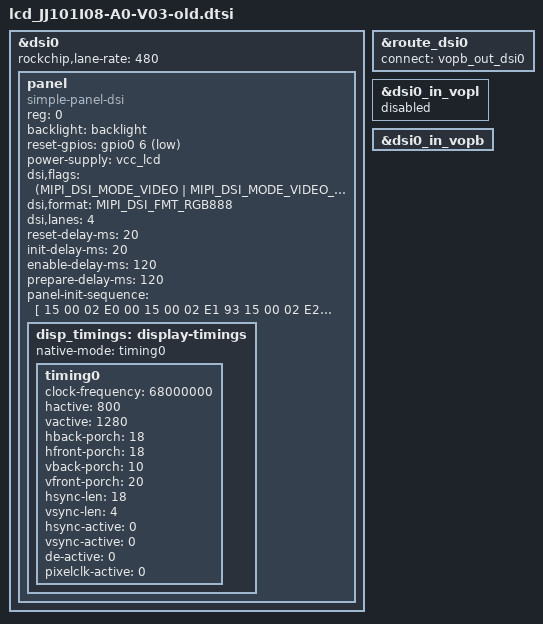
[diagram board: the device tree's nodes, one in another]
/*
***lcd_JJ101I08-A0-V03 20201125 by lxr***
*/
&dsi0 {
	status = "okay";
	rockchip,lane-rate = <480>;

	panel: panel {
		compatible = "simple-panel-dsi";
		reg = <0>;
		backlight = <&backlight>;
		//enable-gpios = <&gpio7 3 GPIO_ACTIVE_HIGH>;
		//reset-gpios = <0>;
		reset-gpios = <&gpio0 6 GPIO_ACTIVE_LOW>;// V2.2A
		power-supply = <&vcc_lcd>;
		dsi,flags = <(MIPI_DSI_MODE_VIDEO | MIPI_DSI_MODE_VIDEO_BURST | MIPI_DSI_MODE_EOT_PACKET | MIPI_DSI_MODE_LPM)>;
		dsi,format = <MIPI_DSI_FMT_RGB888>;
		dsi,lanes = <4>;
		reset-delay-ms = <20>;
		init-delay-ms = <20>;
		enable-delay-ms = <120>;
		prepare-delay-ms = <120>;
		status = "okay";
		
		panel-init-sequence = [
                15 00 02 E0 00 
		15 00 02 E1 93 
		15 00 02 E2 65 
		15 00 02 E3 F8 
		15 00 02 80 03 
		15 00 02 E0 01 
		//15 00 02 00 00 
		15 00 02 01 67 
		//15 00 02 03 00 
		//15 00 02 04 6C 
		15 00 02 17 00 
		15 00 02 18 BF 
		15 00 02 19 01 
		15 00 02 1A 00 
		15 00 02 1B BF 
		15 00 02 1C 01 
		15 00 02 1F 70 
		15 00 02 20 2D 
		15 00 02 21 2D 
		15 00 02 22 7E 
		15 00 02 35 28 
		15 00 02 37 19 
		15 00 02 38 05 
		15 00 02 39 00 
		15 00 02 3A 01 
		15 00 02 3C 7C 
		15 00 02 3D FF 
		15 00 02 3E FF 
		15 00 02 3F 7F 
		15 00 02 40 06 
		15 00 02 41 A0 
		15 00 02 43 1E 
		15 00 02 44 0B 
		15 00 02 45 28 
		15 00 02 55 0F 
		15 00 02 57 A8 
		15 00 02 59 0A 
		15 00 02 5A 2E 
		15 00 02 5B 1A 
		15 00 02 5C 15 
		15 00 02 5D 7F 
		15 00 02 5E 64 
		15 00 02 5F 53 
		15 00 02 60 47 
		15 00 02 61 43 
		15 00 02 62 33 
		15 00 02 63 37 
		15 00 02 64 21 
		15 00 02 65 39 
		15 00 02 66 37 
		15 00 02 67 34 
		15 00 02 68 50 
		15 00 02 69 3D 
		15 00 02 6A 44 
		15 00 02 6B 36 
		15 00 02 6C 34 
		15 00 02 6D 25 
		15 00 02 6E 15 
		15 00 02 6F 02 
		15 00 02 70 7F 
		15 00 02 71 64 
		15 00 02 72 53 
		15 00 02 73 47
		15 00 02 74 43 
		15 00 02 75 33 
		15 00 02 76 37 
		15 00 02 77 21 
		15 00 02 78 39 
		15 00 02 79 37 
		15 00 02 7A 34 
		15 00 02 7B 50 
		15 00 02 7C 3D 
		15 00 02 7D 44 
		15 00 02 7E 36 
		15 00 02 7F 34 
		15 00 02 80 25 
		15 00 02 81 15 
		15 00 02 82 02 
		15 00 02 E0 02 
		15 00 02 00 52 
		15 00 02 01 55 
		15 00 02 02 55 
		15 00 02 03 50 
		15 00 02 04 77 
		15 00 02 05 57 
		15 00 02 06 55 
		15 00 02 07 4E 
		15 00 02 08 4C 
		15 00 02 09 5F 
		15 00 02 0A 4A 
		15 00 02 0B 48 
		15 00 02 0C 55 
		15 00 02 0D 46 
		15 00 02 0E 44 
		15 00 02 0F 40 
		15 00 02 10 55 
		15 00 02 11 55 
		15 00 02 12 55 
		15 00 02 13 55 
		15 00 02 14 55 
		15 00 02 15 55 
		15 00 02 16 53 
		15 00 02 17 55 
		15 00 02 18 55 
		15 00 02 19 51 
		15 00 02 1A 77 
		15 00 02 1B 57 
		15 00 02 1C 55 
		15 00 02 1D 4F 
		15 00 02 1E 4D 
		15 00 02 1F 5F 
		15 00 02 20 4B 
		15 00 02 21 49 
		15 00 02 22 55 
		15 00 02 23 47 
		15 00 02 24 45 
		15 00 02 25 41 
		15 00 02 26 55 
		15 00 02 27 55 
		15 00 02 28 55 
		15 00 02 29 55 
		15 00 02 2A 55 
		15 00 02 2B 55 
		15 00 02 2C 13 
		15 00 02 2D 15 
		15 00 02 2E 15 
		15 00 02 2F 01 
		15 00 02 30 37 
		15 00 02 31 17 
		15 00 02 32 15 
		15 00 02 33 0D 
		15 00 02 34 0F 
		15 00 02 35 15 
		15 00 02 36 05 
		15 00 02 37 07 
		15 00 02 38 15 
		15 00 02 39 09 
		15 00 02 3A 0B 
		15 00 02 3B 11 
		15 00 02 3C 15 
		15 00 02 3D 15 
		15 00 02 3E 15 
		15 00 02 3F 15 
		15 00 02 40 15 
		15 00 02 41 15 
		15 00 02 42 12 
		15 00 02 43 15 
		15 00 02 44 15 
		15 00 02 45 00 
		15 00 02 46 37 
		15 00 02 47 17 
		15 00 02 48 15 
		15 00 02 49 0C 
		15 00 02 4A 0E 
		15 00 02 4B 15 
		15 00 02 4C 04 
		15 00 02 4D 06 
		15 00 02 4E 15 
		15 00 02 4F 08 
		15 00 02 50 0A 
		15 00 02 51 10 
		15 00 02 52 15 
		15 00 02 53 15 
		15 00 02 54 15 
		15 00 02 55 15 
		15 00 02 56 15 
		15 00 02 57 15 
		15 00 02 58 40 
		15 00 02 5B 10 
		15 00 02 5C 06 
		15 00 02 5D 40 
		15 00 02 5E 00 
		15 00 02 5F 00 
		15 00 02 60 40 
		15 00 02 61 03 
		15 00 02 62 04 
		15 00 02 63 6C 
		15 00 02 64 6C 
		15 00 02 65 75 
		15 00 02 66 08 
		15 00 02 67 B4 
		15 00 02 68 08 
		15 00 02 69 6C 
		15 00 02 6A 6C 
		15 00 02 6B 0C 
		15 00 02 6D 00 
		15 00 02 6E 00 
		15 00 02 6F 88 
		15 00 02 75 BB 
		15 00 02 76 00 
		15 00 02 77 05 
		15 00 02 78 2A 
		15 00 02 E0 04 
		15 00 02 09 11 
		15 00 02 0E 48 
		15 00 02 2B 2B 
		15 00 02 2D 03 
		15 00 02 2E 44 
		15 00 02 E0 05 
		15 00 02 12 72 
		15 00 02 E0 00 
		15 00 02 E6 02 
		15 00 02 E7 0C 
		05 78 01 11
		05 14 01 29    
		    ];  
			
		disp_timings: display-timings {
			native-mode = <&timing0>;

			timing0: timing0 {
				clock-frequency = <68000000>;
				hactive = <800>;
				vactive = <1280>;
				hback-porch = <18>;
				hfront-porch = <18>;
				vback-porch = <10>;
				vfront-porch = <20>;
				hsync-len = <18>;
				vsync-len = <4>;
				hsync-active = <0>;
				vsync-active = <0>;
				de-active = <0>;
				pixelclk-active = <0>;
			};
		};	    
	};              
};        

&route_dsi0 {
	status = "okay";
    connect = <&vopb_out_dsi0>;
};       
&dsi0_in_vopl{
    status = "disabled";
};       
   
&dsi0_in_vopb{
    status = "okay";
};
